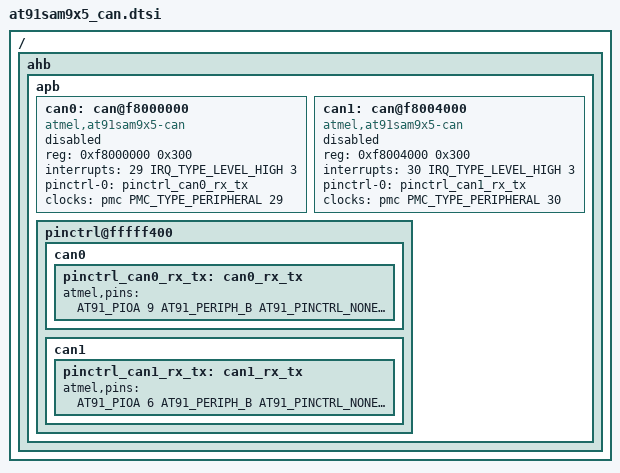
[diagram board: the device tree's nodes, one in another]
// SPDX-License-Identifier: GPL-2.0-only
/*
 * at91sam9x5_can.dtsi - Device Tree Include file for AT91SAM9x5 SoC with 1
 * Ethernet interface.
 *
 * Copyright (C) 2013 Boris BREZILLON <b.brezillon@overkiz.com>
 */

#include <dt-bindings/pinctrl/at91.h>
#include <dt-bindings/interrupt-controller/irq.h>

/ {
	ahb {
		apb {
			can0: can@f8000000 {
				compatible = "atmel,at91sam9x5-can";
				reg = <0xf8000000 0x300>;
				interrupts = <29 IRQ_TYPE_LEVEL_HIGH 3>;
				pinctrl-names = "default";
				pinctrl-0 = <&pinctrl_can0_rx_tx>;
				clocks = <&pmc PMC_TYPE_PERIPHERAL 29>;
				clock-names = "can_clk";
				status = "disabled";
			};

			can1: can@f8004000 {
				compatible = "atmel,at91sam9x5-can";
				reg = <0xf8004000 0x300>;
				interrupts = <30 IRQ_TYPE_LEVEL_HIGH 3>;
				pinctrl-names = "default";
				pinctrl-0 = <&pinctrl_can1_rx_tx>;
				clocks = <&pmc PMC_TYPE_PERIPHERAL 30>;
				clock-names = "can_clk";
				status = "disabled";
			};

			pinctrl@fffff400 {
				can0 {
					pinctrl_can0_rx_tx: can0_rx_tx {
						atmel,pins =
							<AT91_PIOA 9 AT91_PERIPH_B AT91_PINCTRL_NONE	/* CANRX0, conflicts with DRXD */
							AT91_PIOA 10 AT91_PERIPH_B AT91_PINCTRL_NONE>;	/* CANTX0, conflicts with DTXD */
					};
				};

				can1 {
					pinctrl_can1_rx_tx: can1_rx_tx {
						atmel,pins =
							<AT91_PIOA 6 AT91_PERIPH_B AT91_PINCTRL_NONE	/* CANRX1, conflicts with RXD1 */
							AT91_PIOA 5 AT91_PERIPH_B AT91_PINCTRL_NONE>;	/* CANTX1, conflicts with TXD1 */
					};
				};
			};
		};
	};
};
